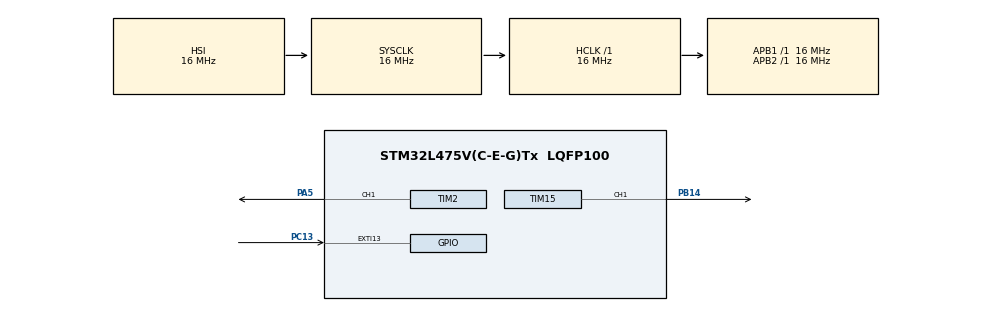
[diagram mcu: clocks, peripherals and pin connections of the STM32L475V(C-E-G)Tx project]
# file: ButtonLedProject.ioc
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Mcu.Family=STM32L4
Mcu.Name=STM32L475V(C-E-G)Tx
Mcu.Package=LQFP100
NVIC.EXTI15_10_IRQn=true\:0\:0\:false\:false\:true\:true\:true
NVIC.PriorityGroup=NVIC_PRIORITYGROUP_4
PA5.Signal=S_TIM2_CH1
PB14.Signal=S_TIM15_CH1
PC13.Signal=GPXTI13
ProjectManager.HeapSize=0x200
ProjectManager.StackSize=0x400
ProjectManager.TargetToolchain=EWARM V8.32
RCC.ADCFreq_Value=48000000
RCC.AHBFreq_Value=16000000
RCC.APB1Freq_Value=16000000
RCC.APB1TimFreq_Value=16000000
RCC.APB2Freq_Value=16000000
RCC.APB2TimFreq_Value=16000000
RCC.CortexFreq_Value=16000000
RCC.HCLKFreq_Value=16000000
RCC.HSE_VALUE=8000000
RCC.HSI_VALUE=16000000
RCC.MSI_VALUE=4000000
RCC.PLLN=40
RCC.PLLSAI1N=24
RCC.SYSCLKFreq_VALUE=16000000
RCC.SYSCLKSource=RCC_SYSCLKSOURCE_HSI
RCC.USBFreq_Value=48000000
RCC.VCOOutputFreq_Value=160000000
SH.S_TIM15_CH1.0=TIM15_CH1,PWM Generation1 CH1
SH.S_TIM2_CH1.0=TIM2_CH1,PWM Generation1 CH1
TIM15.Channel-PWM\ Generation1\ CH1=TIM_CHANNEL_1
TIM15.Period=2000-1
TIM15.Prescaler=160-1
TIM2.Channel-PWM\ Generation1\ CH1=TIM_CHANNEL_1
TIM2.Period=2000-1
TIM2.Prescaler=160-1
VP_TIM15_VS_ClockSourceINT.Mode=Internal
VP_TIM2_VS_ClockSourceINT.Mode=Internal
board=B-L475E-IOT01A1

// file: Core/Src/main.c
/* USER CODE BEGIN Header */
/**
  ******************************************************************************
  * @file           : main.c
  * @brief          : Main program body
  ******************************************************************************
  * @attention
  *
  * <h2><center>&copy; Copyright (c) 2020 STMicroelectronics.
  * All rights reserved.</center></h2>
  *
  * This software component is licensed by ST under BSD 3-Clause license,
  * the "License"; You may not use this file except in compliance with the
  * License. You may obtain a copy of the License at:
  *                        opensource.org/licenses/BSD-3-Clause
  *
  ******************************************************************************
  */
/* USER CODE END Header */
#include "main.h"

TIM_HandleTypeDef htim2;
TIM_HandleTypeDef htim15;

void SystemClock_Config(void);
static void MX_GPIO_Init(void);
static void MX_TIM2_Init(void);
static void MX_TIM15_Init(void);

/* USER CODE BEGIN 0 */
void user_pwm_setvalue(TIM_HandleTypeDef* htim, uint16_t pwm_value, uint16_t channel);
void configure_led_gpio_state(TIM_HandleTypeDef* htim, LED_State state_machine);

volatile LED_State state_machine;
/* USER CODE END 0 */

int main(void)
{
  /* USER CODE BEGIN 1 */
  int32_t pwm_value = 0, step = 0;
  /* USER CODE END 1 */

  /* MCU Configuration--------------------------------------------------------*/

  /* Reset of all peripherals, Initializes the Flash interface and the Systick. */
  HAL_Init();

  /* Configure the system clock */
  SystemClock_Config();

  /* Initialize all configured peripherals */
  MX_GPIO_Init();
  MX_TIM2_Init();
  MX_TIM15_Init();
  /* USER CODE BEGIN 2 */

  // Initialize the LED State Machine to RESET_OFF Mode
  state_machine = RESET_OFF;

  HAL_TIM_PWM_Start(&htim2, TIM_CHANNEL_1);
  HAL_TIM_PWM_Start(&htim15, TIM_CHANNEL_1);

  /* USER CODE END 2 */

  /* Infinite loop */
  while (1)
  {

    /* USER CODE BEGIN 3 */

      // Based on state, set the GPIO modes
      configure_led_gpio_state(&htim2, state_machine);
      configure_led_gpio_state(&htim15, state_machine);

      // Implementation of statemachine function
      switch(state_machine)
      {
          case RESET_OFF:
                HAL_GPIO_WritePin(GPIOA, GPIO_PIN_5, GPIO_PIN_RESET);
                HAL_GPIO_WritePin(GPIOB, GPIO_PIN_14, GPIO_PIN_RESET);
                break;
          case SOLID_ON:
                HAL_GPIO_WritePin(GPIOA, GPIO_PIN_5, GPIO_PIN_SET);
                HAL_GPIO_WritePin(GPIOB, GPIO_PIN_14, GPIO_PIN_SET);
                break;
          case BLINK_SLOW:
                HAL_GPIO_TogglePin(GPIOA, GPIO_PIN_5);
                HAL_GPIO_TogglePin(GPIOB, GPIO_PIN_14);
                HAL_Delay(500);
                break;
          case BLINK_FAST:
                HAL_GPIO_TogglePin(GPIOA, GPIO_PIN_5);
                HAL_GPIO_TogglePin(GPIOB, GPIO_PIN_14);
                HAL_Delay(100);
                break;
         case DIM_SLOW:
                HAL_Delay(50);
                if(pwm_value == 0) step = 100;
                if(pwm_value == 2000) step = -100;
                pwm_value += step;
                user_pwm_setvalue(&htim2, pwm_value, TIM_CHANNEL_1);
                user_pwm_setvalue(&htim15, pwm_value, TIM_CHANNEL_1);
                break;
         case DIM_FAST:
                HAL_Delay(5);
                if(pwm_value == 0) step = 100;
                if(pwm_value == 2000) step = -100;
                pwm_value += step;
                user_pwm_setvalue(&htim2, pwm_value, TIM_CHANNEL_1);
                user_pwm_setvalue(&htim15, pwm_value, TIM_CHANNEL_1);
                break;
         default:
                /* Do Nothing */
                break;
      }
  }
  /* USER CODE END 3 */
}

void SystemClock_Config(void)
{
  RCC_OscInitTypeDef RCC_OscInitStruct = {0};
  RCC_ClkInitTypeDef RCC_ClkInitStruct = {0};

  /** Initializes the RCC Oscillators according to the specified parameters
  * in the RCC_OscInitTypeDef structure.
  */
  RCC_OscInitStruct.OscillatorType = RCC_OSCILLATORTYPE_HSI;
  RCC_OscInitStruct.HSIState = RCC_HSI_ON;
  RCC_OscInitStruct.HSICalibrationValue = RCC_HSICALIBRATION_DEFAULT;
  RCC_OscInitStruct.PLL.PLLState = RCC_PLL_NONE;
  if (HAL_RCC_OscConfig(&RCC_OscInitStruct) != HAL_OK)
  {
    Error_Handler();
  }
  /** Initializes the CPU, AHB and APB buses clocks
  */
  RCC_ClkInitStruct.ClockType = RCC_CLOCKTYPE_HCLK|RCC_CLOCKTYPE_SYSCLK
                              |RCC_CLOCKTYPE_PCLK1|RCC_CLOCKTYPE_PCLK2;
  RCC_ClkInitStruct.SYSCLKSource = RCC_SYSCLKSOURCE_HSI;
  RCC_ClkInitStruct.AHBCLKDivider = RCC_SYSCLK_DIV1;
  RCC_ClkInitStruct.APB1CLKDivider = RCC_HCLK_DIV1;
  RCC_ClkInitStruct.APB2CLKDivider = RCC_HCLK_DIV1;

  if (HAL_RCC_ClockConfig(&RCC_ClkInitStruct, FLASH_LATENCY_0) != HAL_OK)
  {
    Error_Handler();
  }
  /** Configure the main internal regulator output voltage
  */
  if (HAL_PWREx_ControlVoltageScaling(PWR_REGULATOR_VOLTAGE_SCALE1) != HAL_OK)
  {
    Error_Handler();
  }
}

static void MX_TIM2_Init(void)
{

  TIM_ClockConfigTypeDef sClockSourceConfig = {0};
  TIM_MasterConfigTypeDef sMasterConfig = {0};
  TIM_OC_InitTypeDef sConfigOC = {0};

  htim2.Instance = TIM2;
  htim2.Init.Prescaler = 160-1;
  htim2.Init.CounterMode = TIM_COUNTERMODE_UP;
  htim2.Init.Period = 2000-1;
  htim2.Init.ClockDivision = TIM_CLOCKDIVISION_DIV1;
  htim2.Init.AutoReloadPreload = TIM_AUTORELOAD_PRELOAD_ENABLE;
  if (HAL_TIM_Base_Init(&htim2) != HAL_OK)
  {
    Error_Handler();
  }
  sClockSourceConfig.ClockSource = TIM_CLOCKSOURCE_INTERNAL;
  if (HAL_TIM_ConfigClockSource(&htim2, &sClockSourceConfig) != HAL_OK)
  {
    Error_Handler();
  }
  if (HAL_TIM_PWM_Init(&htim2) != HAL_OK)
  {
    Error_Handler();
  }
  sMasterConfig.MasterOutputTrigger = TIM_TRGO_RESET;
  sMasterConfig.MasterSlaveMode = TIM_MASTERSLAVEMODE_DISABLE;
  if (HAL_TIMEx_MasterConfigSynchronization(&htim2, &sMasterConfig) != HAL_OK)
  {
    Error_Handler();
  }
  sConfigOC.OCMode = TIM_OCMODE_PWM1;
  sConfigOC.Pulse = 0;
  sConfigOC.OCPolarity = TIM_OCPOLARITY_HIGH;
  sConfigOC.OCFastMode = TIM_OCFAST_DISABLE;
  if (HAL_TIM_PWM_ConfigChannel(&htim2, &sConfigOC, TIM_CHANNEL_1) != HAL_OK)
  {
    Error_Handler();
  }
  HAL_TIM_MspPostInit(&htim2);

}

static void MX_TIM15_Init(void)
{

  TIM_ClockConfigTypeDef sClockSourceConfig = {0};
  TIM_MasterConfigTypeDef sMasterConfig = {0};
  TIM_OC_InitTypeDef sConfigOC = {0};
  TIM_BreakDeadTimeConfigTypeDef sBreakDeadTimeConfig = {0};

  htim15.Instance = TIM15;
  htim15.Init.Prescaler = 160-1;
  htim15.Init.CounterMode = TIM_COUNTERMODE_UP;
  htim15.Init.Period = 2000-1;
  htim15.Init.ClockDivision = TIM_CLOCKDIVISION_DIV1;
  htim15.Init.RepetitionCounter = 0;
  htim15.Init.AutoReloadPreload = TIM_AUTORELOAD_PRELOAD_ENABLE;
  if (HAL_TIM_Base_Init(&htim15) != HAL_OK)
  {
    Error_Handler();
  }
  sClockSourceConfig.ClockSource = TIM_CLOCKSOURCE_INTERNAL;
  if (HAL_TIM_ConfigClockSource(&htim15, &sClockSourceConfig) != HAL_OK)
  {
    Error_Handler();
  }
  if (HAL_TIM_PWM_Init(&htim15) != HAL_OK)
  {
    Error_Handler();
  }
  sMasterConfig.MasterOutputTrigger = TIM_TRGO_RESET;
  sMasterConfig.MasterSlaveMode = TIM_MASTERSLAVEMODE_DISABLE;
  if (HAL_TIMEx_MasterConfigSynchronization(&htim15, &sMasterConfig) != HAL_OK)
  {
    Error_Handler();
  }
  sConfigOC.OCMode = TIM_OCMODE_PWM1;
  sConfigOC.Pulse = 0;
  sConfigOC.OCPolarity = TIM_OCPOLARITY_HIGH;
  sConfigOC.OCNPolarity = TIM_OCNPOLARITY_HIGH;
  sConfigOC.OCFastMode = TIM_OCFAST_DISABLE;
  sConfigOC.OCIdleState = TIM_OCIDLESTATE_RESET;
  sConfigOC.OCNIdleState = TIM_OCNIDLESTATE_RESET;
  if (HAL_TIM_PWM_ConfigChannel(&htim15, &sConfigOC, TIM_CHANNEL_1) != HAL_OK)
  {
    Error_Handler();
  }
  sBreakDeadTimeConfig.OffStateRunMode = TIM_OSSR_DISABLE;
  sBreakDeadTimeConfig.OffStateIDLEMode = TIM_OSSI_DISABLE;
  sBreakDeadTimeConfig.LockLevel = TIM_LOCKLEVEL_OFF;
  sBreakDeadTimeConfig.DeadTime = 0;
  sBreakDeadTimeConfig.BreakState = TIM_BREAK_DISABLE;
  sBreakDeadTimeConfig.BreakPolarity = TIM_BREAKPOLARITY_HIGH;
  sBreakDeadTimeConfig.AutomaticOutput = TIM_AUTOMATICOUTPUT_DISABLE;
  if (HAL_TIMEx_ConfigBreakDeadTime(&htim15, &sBreakDeadTimeConfig) != HAL_OK)
  {
    Error_Handler();
  }
  HAL_TIM_MspPostInit(&htim15);

}

static void MX_GPIO_Init(void)
{
  GPIO_InitTypeDef GPIO_InitStruct = {0};

  /* GPIO Ports Clock Enable */
  __HAL_RCC_GPIOC_CLK_ENABLE();
  __HAL_RCC_GPIOA_CLK_ENABLE();
  __HAL_RCC_GPIOB_CLK_ENABLE();

  /*Configure GPIO pin : PC13 */
  GPIO_InitStruct.Pin = GPIO_PIN_13;
  GPIO_InitStruct.Mode = GPIO_MODE_IT_RISING;
  GPIO_InitStruct.Pull = GPIO_NOPULL;
  HAL_GPIO_Init(GPIOC, &GPIO_InitStruct);

  /* EXTI interrupt init*/
  HAL_NVIC_SetPriority(EXTI15_10_IRQn, 0, 0);
  HAL_NVIC_EnableIRQ(EXTI15_10_IRQn);

}

/* USER CODE BEGIN 4 */
/**
  * @brief GPIO Exti Callback Implementation
  * @param GPIO Pin Value
  * @retval None
  */
void HAL_GPIO_EXTI_Callback(uint16_t GPIO_Pin)
{
    switch(state_machine)
    {
        case RESET_OFF:
            state_machine = SOLID_ON;
            break;
        case SOLID_ON:
            state_machine = BLINK_SLOW;
            break;
        case BLINK_SLOW:
            state_machine = BLINK_FAST;
            break;
        case BLINK_FAST:
            state_machine = DIM_SLOW;
            break;
        case DIM_SLOW:
            state_machine = DIM_FAST;
            break;
        case DIM_FAST:
            state_machine = RESET_OFF;
            break;
        default:
            state_machine = RESET_OFF;
    }
}

/**
  * @brief Resets PWM Value by updating corresponding CCR register content
  * @param pwm_value - new CCR value, channel - Corresponding Channel for update (care should be taken, not all timers has 4 channels)
  * @retval None
  */
void user_pwm_setvalue(TIM_HandleTypeDef* htim, uint16_t pwm_value, uint16_t channel)
{
    switch (channel)
    {
        case TIM_CHANNEL_1:
        {
            htim->Instance->CCR1 = pwm_value;
            //HAL_TIM_PWM_ConfigChannel(htim, &sConfigOC, channel);
            break;
        }

        case TIM_CHANNEL_2:
        {
            htim->Instance->CCR2 = pwm_value;
            break;
        }

        case TIM_CHANNEL_3:
        {
            htim->Instance->CCR3 = pwm_value;
            break;
        }

        case TIM_CHANNEL_4:
        {
            htim->Instance->CCR1 = pwm_value;
            break;
        }

        default:
        break;
    }
}

/**
  * @brief Configuring GPIO Mode, origininally initialized to timer
  * @param Timer Instance, state of the state-machine
  * @retval None
  */
void configure_led_gpio_state(TIM_HandleTypeDef* htim, LED_State state_machine)
{
    uint32_t gpio_mode = 0, gpio_type = 0;
    if((state_machine == RESET_OFF) || (state_machine == SOLID_ON)
        || (state_machine == BLINK_SLOW) || (state_machine == BLINK_FAST))
    {
        gpio_type = GPIO_MODE_OUTPUT_PP;
    }
    else
    {
        gpio_type = GPIO_MODE_AF_PP;
    }

    if(htim->Instance==TIM2)
    {
        //GPIOA -> GPIO_PIN_5
        gpio_mode = GPIOA->MODER;
        gpio_mode &= ~(0x3 << 10);
        gpio_mode |= (gpio_type << 10);
        GPIOA->MODER = gpio_mode;
    }
    else if(htim->Instance==TIM15)
    {
        //GPIOB -> GPIO_PIN_14
        gpio_mode = GPIOB->MODER;
        gpio_mode &= ~(0x3 << 28);
        gpio_mode |= (gpio_type << 28);
        GPIOB->MODER = gpio_mode;
    }
}

/* USER CODE END 4 */

void Error_Handler(void)
{
}

/************************ (C) COPYRIGHT STMicroelectronics *****END OF FILE****/
